# CY8C5568AXI_060 register map
File version: 0.1
CY8C55
Registers are 8-bit, read-write, no defined reset value unless marked. A register's access mark holds for its fields unless they carry their own. Offsets are from the block's base; lines under a group give offsets from that group; [hi:lo] are bit positions; {n}, {i} and the like mark numbered series; 'fields as' and 'values as' point back to an identical list; <NAME> marks a mode.

## Memory map
0x400043A3 Counter_2 size 0xB62
0x400043AA ADC_DelSig_V size 0x17E0
0x40004616 ADC_SAR_I size 0x158D — SAR ADC
0x40006404 SPIS_1 size 0x164
0x40006422 UART_1 size 0x145 — UART
0x40006473 Control_Reg_1 size 0x1
0x40006524 PWM_BUCK size 0x72
0x4000C784 DFB_1 size 0x2B

## SPIS_1
Base 0x40006404
0x00 SPIS_1_RX_DATA — SPIS RX Data
0x01 SPIS_1_TX_DATA — SPIS TX Data
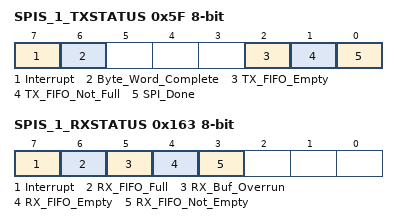
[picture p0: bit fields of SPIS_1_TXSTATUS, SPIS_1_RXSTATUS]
0x5F SPIS_1_TXSTATUS — SPIS TX Status Register
  [7] Interrupt ro — Set when interrupt occurs
  [6] Byte_Word_Complete ro — Set when a byte/word transmit has completed
  [2] TX_FIFO_Empty ro — Set when the TX Data FIFO is empty
  [1] TX_FIFO_Not_Full ro — Set when the TX Data FIFO is not full
  [0] SPI_Done ro — Set when all of the data in the transmit FIFO has been sent. Set when Byte/Word Complete has been set and TX Data FIFO is empty
0x163 SPIS_1_RXSTATUS — SPIS RX Status Register
  [7] Interrupt ro — Set when interrupt occurs
  [6] RX_FIFO_Full ro — Set when the RX Data FIFO is full
  [5] RX_Buf_Overrun ro — Set when RX Data has overrun the 4 byte/word FIFO without being moved to the RX buffer memory array (if one exists)
  [4] RX_FIFO_Empty ro — Set when the RX Data FIFO is empty
  [3] RX_FIFO_Not_Empty ro — Set when the RX Data FIFO is not empty. That is, at least one byte/word is in the RX FIFO (does not indicate the RX buffer RAM array conditions)

## Counter_2
Base 0x400043A3
0x00 Counter_2_GLOBAL_ENABLE — PM.ACT.CFG
  [3:0] en_timer — Enable timer/counters.
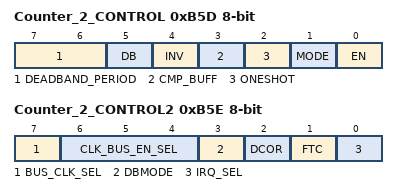
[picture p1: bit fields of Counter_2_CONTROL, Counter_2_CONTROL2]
0xB5D Counter_2_CONTROL — TMRx.CFG0
  [7:6] DEADBAND_PERIOD
  [5] DB — Deadband mode--Deadband phases phi1 and phi2 are outputted on CMP and TC output pins respectively.
    0=Timer (CMP and TC are output.); 1=Deadband (PHI1 (instead of CMP) and PHI2 (instead of TC) are output.)
  [4] INV — Invert sense of TIMEREN signal
  [3] CMP_BUFF — Buffer compare register. Compare register updates only on timer terminal count.
  [2] ONESHOT — Timer stops upon reaching stop condition defined by TMR_CFG bits. Can be restarted by asserting TIMER RESET or disabling and re-enabling block.
  [1] MODE — Mode. (0 = Timer; 1 = Comparator)
    0=Timer mode. CNT/CMP register holds timer count value.; 1=Comparator mode. CNT/CMP register holds comparator threshold value.
  [0] EN — Enables timer/comparator.
0xB5E Counter_2_CONTROL2 — TMRx.CFG1
  [7] BUS_CLK_SEL — Bus Clock selection.
  [6:4] CLK_BUS_EN_SEL — Digital Global Clock selection.
  [3] DBMODE — Deadband mode (asynchronous/synchronous). CMP output pin is also affected when not in deadband mode (CFG0.DEADBAND).
  [2] DCOR — Disable Clear on Read (DCOR) of Status Register SR0.
  [1] FTC — First Terminal Count (FTC). Setting this bit forces a single pulse on the TC pin when first enabled.
    0=Disable_FTC (Disable the single cycle pulse, which signifies the timer is starting.); 1=Enable_FTC (Enable the single cycle pulse, which signifies the timer is starting.)
  [0] IRQ_SEL — Irq selection. (0 = raw interrupts; 1 = status register interrupts)
0xB5F Counter_2_PERIOD — TMRx.PER0 - Assigned Period
0xB61 Counter_2_COUNTER — TMRx.CNT_CMP0 - Current Down Counter Value

## ADC_SAR_I — SAR ADC
Base 0x40004616
0x00 SAR_TR0 — SAR trim register
{0x12F2+i} SAR_CSR{i} (i=0..6) — SAR status and control register {i}
0x1512 SAR_SW0 — SAR Analog Routing Register 0
{0x1512+i} SAR_SW{i} (i=2..4) — SAR Analog Routing Register {i}
0x1518 SAR_SW6 — SAR Analog Routing Register 6
0x1519 SAR_CLK — SAR Clock Selection Register
0x158C SAR_WRK 16-bit — SAR working register

## PWM_BUCK
Base 0x40006524
0x00 PWM_BUCK_COMPARE_Reg 16-bit — UDB.D0 - Assigned Compare Value
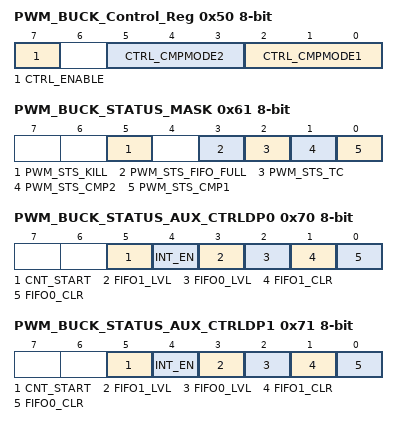
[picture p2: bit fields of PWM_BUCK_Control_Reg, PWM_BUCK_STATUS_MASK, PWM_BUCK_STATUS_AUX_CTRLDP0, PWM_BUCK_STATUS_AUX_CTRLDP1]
0x50 PWM_BUCK_Control_Reg — UDB Control Register - Assigned Control Register Value
  [7] CTRL_ENABLE — Enable the PWM
  [5:3] CTRL_CMPMODE2 — Compare mode 2
  [2:0] CTRL_CMPMODE1 — Compare mode 1
0x61 PWM_BUCK_STATUS_MASK — UDB Status bits Interrupt Mask Enable Register
  [5] PWM_STS_KILL ro — Enables the Interrupt on Kill
  [3] PWM_STS_FIFO_FULL ro — FIFO Full Status Mask
  [2] PWM_STS_TC ro — Enables the Interrupt on Terminal Count
  [1] PWM_STS_CMP2 ro — Enables the Interrupt on Compare 2
  [0] PWM_STS_CMP1 ro — Enables the Interrupt on Compare 1
0x70 PWM_BUCK_STATUS_AUX_CTRLDP0 — UDB Auxilliary Control Register
  [5] CNT_START — FIFO0 clear
    0=E_CNT_START0 (Disable counter); 1=E_CNT_START1 (Enable counter)
  [4] INT_EN
    0=E_INT_EN0 (Interrupt disabled); 1=E_INT_EN1 (Interrupt enabled)
  [3] FIFO1_LVL — FIFO level
    0=E_FIFO_LVL_0 (FIFO LVL: input mode: FIFO not full; output mode: FIFO not empty); 1=E_FIFO_LVL_1 (FIFO LVL: input mode: FIFO at least 1/2 empty; output mode: FIFO at least 1/2 full)
  [2] FIFO0_LVL — FIFO level
    values as FIFO1_LVL
  [1] FIFO1_CLR — FIFO1 clear
    0=E_FIFO_CLR_0 (Normal FIFO operation); 1=E_FIFO_CLR_1 (Clear FIFO state)
  [0] FIFO0_CLR — FIFO0 clear
    values as FIFO1_CLR
0x71 PWM_BUCK_STATUS_AUX_CTRLDP1 — UDB Auxilliary Control Register
  fields as PWM_BUCK_STATUS_AUX_CTRLDP0
